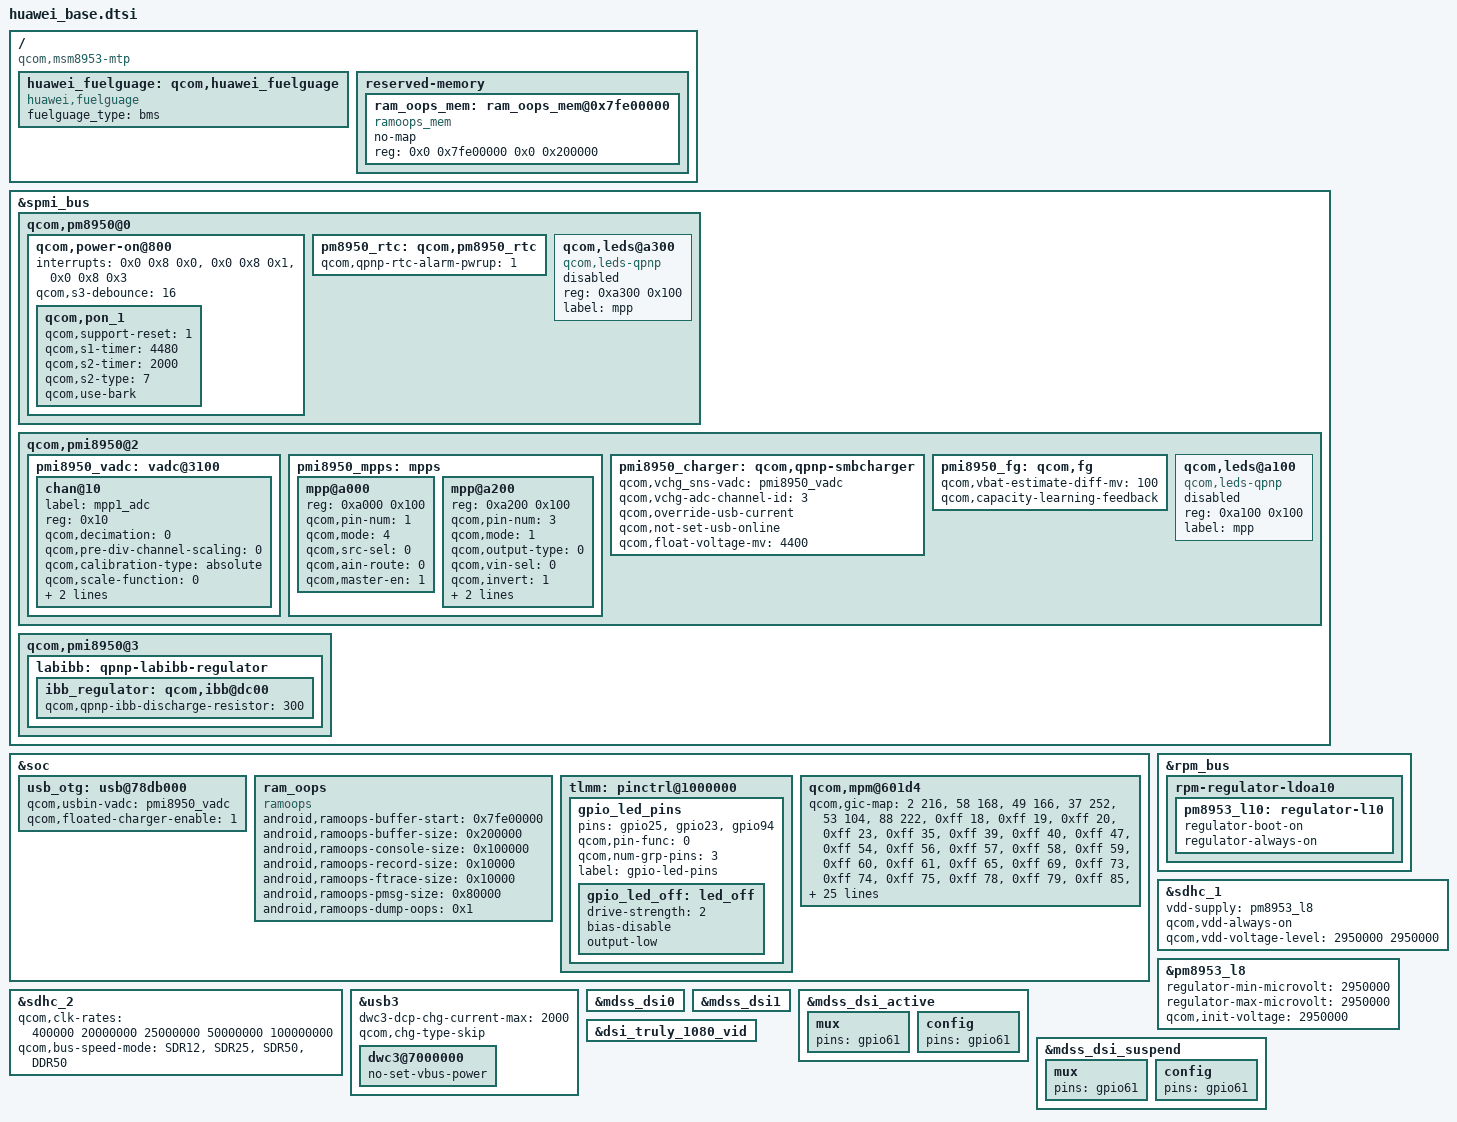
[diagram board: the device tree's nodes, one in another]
/*=============================================================================

                              Huawei Base Dtsi File

GENERAL DESCRIPTION
  This file is for include the Communal node

Copyright 2010-2014 by HUAWEI Technologies, Inc.  All Rights Reserved.
=============================================================================*/
#include "huawei_antenna_board_detect.dtsi"
#include "msm8953.dtsi"
#include "msm8953-mtp.dtsi"

/ {
	compatible = "qcom,msm8953-mtp", "qcom,msm8953", "qcom,mtp";
};

&spmi_bus {

	qcom,pm8950@0 {
		qcom,power-on@800 {
			interrupts = <0x0 0x8 0x0>,
				<0x0 0x8 0x1>,
				<0x0 0x8 0x3>;
			interrupt-names = "kpdpwr", "resin","kpdpwr-bark";
			qcom,s3-debounce = <16>;

			qcom,pon_1 {
				qcom,support-reset = <1>;
				qcom,s1-timer = <4480>;
				qcom,s2-timer = <2000>;
				qcom,s2-type = <7>;
				qcom,use-bark;
			};
		};

		pm8950_rtc: qcom,pm8950_rtc {
			qcom,qpnp-rtc-alarm-pwrup = <1>;
		};

		qcom,leds@a300 {
			compatible = "qcom,leds-qpnp";
			reg = <0xa300 0x100>;
			label = "mpp";
			status = "disabled";
		};
	};

	qcom,pmi8950@2 {
		pmi8950_vadc: vadc@3100 {
			chan@10 {
				label = "mpp1_adc";
				reg = <0x10>; // channel for MPP1
				qcom,decimation = <0>;
				qcom,pre-div-channel-scaling = <0>; //Use 1:1 scaling to keep input voltage with in Max voltage: 1.8V
				qcom,calibration-type = "absolute";
				qcom,scale-function = <0>;
				qcom,hw-settle-time = <1>;
				qcom,fast-avg-setup = <2>;
			};
		};

		pmi8950_mpps: mpps {
			mpp@a000 {
				reg = <0xa000 0x100>;
				qcom,pin-num = <1>;
				status = "ok";
				qcom,mode = <4>; // A-input
				qcom,src-sel = <0>; //MPP Constant
				qcom,ain-route = <0>; // QPNP_PIN_AIN_AMUX_CH5 = 0 for MPP1
				qcom,master-en = <1>; //Enable MPP
			};
			mpp@a200 {
				reg = <0xa200 0x100>;
				qcom,pin-num = <3>;
				qcom,mode = <1>;
				qcom,output-type = <0>;
				qcom,vin-sel = <0>;
				qcom,invert = <1>;
				qcom,src-sel = <0>;
				qcom,master-en = <1>;
				status = "okay";
			};
		};

		pmi8950_charger: qcom,qpnp-smbcharger {
			qcom,vchg_sns-vadc = <&pmi8950_vadc>;
			qcom,vchg-adc-channel-id = <3>;
			qcom,override-usb-current;
			qcom,not-set-usb-online;
			qcom,float-voltage-mv = <4400>;
		};

		pmi8950_fg: qcom,fg {
			qcom,vbat-estimate-diff-mv = <100>;
                        qcom,capacity-learning-feedback;
		};

		qcom,leds@a100 {
			compatible = "qcom,leds-qpnp";
			reg = <0xa100 0x100>;
			label = "mpp";
			status = "disabled";
		};
	};
	qcom,pmi8950@3 {
		labibb: qpnp-labibb-regulator {
			ibb_regulator: qcom,ibb@dc00 {
				qcom,qpnp-ibb-discharge-resistor = <300>;
			};
		};
	};
};

/{
	huawei_fuelguage: qcom,huawei_fuelguage{
		compatible = "huawei,fuelguage";
		fuelguage_type = "bms";
		status = "okay";
	};
};

&soc {
	usb_otg: usb@78db000 {
		qcom,usbin-vadc = <&pmi8950_vadc>;
		qcom,floated-charger-enable = <1>;
	};
};

/{
	reserved-memory {
		ram_oops_mem: ram_oops_mem@0x7fe00000 {
		   compatible = "ramoops_mem";
		   no-map;
		   reg = <0x0 0x7fe00000 0x0 0x200000>;
		 };
	};
};

&soc {
	 ram_oops {
		  compatible = "ramoops";
		  android,ramoops-buffer-start 	= <0x7fe00000>;
		  android,ramoops-buffer-size 	= <0x200000>;
		  android,ramoops-console-size 	= <0x100000>;
		  android,ramoops-record-size 	= <0x10000>;
		  android,ramoops-ftrace-size 	= <0x10000>;
		  android,ramoops-pmsg-size 	= <0x80000>;
		  android,ramoops-dump-oops 	= <0x1>;
	 };
};

&soc {
	tlmm: pinctrl@1000000 {
		gpio_led_pins {
			pins ="gpio25", "gpio23", "gpio94";
			qcom,pin-func = <0>;
			qcom,num-grp-pins = <3>;
			label = "gpio-led-pins";
			gpio_led_off: led_off {
				drive-strength = <2>;
				bias-disable;
				output-low;
			};
		};
	};
};

&rpm_bus {
	rpm-regulator-ldoa10 {
		pm8953_l10: regulator-l10 {
			regulator-boot-on;
			regulator-always-on;
		};
	};
};

&sdhc_1 {
	/* device core power supply */
	vdd-supply = <&pm8953_l8>;
	qcom,vdd-always-on;
	qcom,vdd-voltage-level = <2950000 2950000>;
};

&sdhc_2 {
	/* device core power supply */
	qcom,clk-rates = <400000 20000000 25000000 50000000 100000000>;
	qcom,bus-speed-mode = "SDR12", "SDR25", "SDR50", "DDR50";
};


&pm8953_l8 {
	regulator-min-microvolt = <2950000>;
	regulator-max-microvolt = <2950000>;
	qcom,init-voltage = <2950000>;
};

&soc {
	qcom,mpm@601d4 {
		qcom,gic-map = <2 216>, /* tsens_upper_lower_int */
			<58 168>,   /* qusb2phy_dmse_hv -> hs_phy_irq*/
			<49 166>,   /* qusb2phy_dpse_hv -> usb30_pwr_evnt_irq */
			<37 252>,   /* qmp_usb3_lfps_rxterm_irq -> ss_phy_irq */
			<53 104>, /* mdss_irq */
			<88 222>, /* ee0_krait_hlos_spmi_periph_irq */
			<0xff 18>,  /* APC_qgicQTmrSecPhysIrptReq */
			<0xff 19>,  /* APC_qgicQTmrNonSecPhysIrptReq */
			<0xff 20>,  /* qgicQTmrVirtIrptReq */
			<0xff 23>,  /* apss_hm */
			<0xff 35>,  /* WDT_barkInt */
			<0xff 39>,  /* arch_mem_timer */
			<0xff 40>,  /* qtmr_phy_irq[0] */
			<0xff 47>,  /* rbif_irq[0] */
			<0xff 54>,  /* gladiator-error */
			<0xff 56>,  /* q6_wdog_expired_irq */
			<0xff 57>,  /* mss_to_apps_irq(0) */
			<0xff 58>,  /* mss_to_apps_irq(1) */
			<0xff 59>,  /* mss_to_apps_irq(2) */
			<0xff 60>,  /* mss_to_apps_irq(3) */
			<0xff 61>,  /* mss_a2_bam_irq */
			<0xff 65>,  /* o_gc_sys_irq[0] */
			<0xff 69>,  /* vbif_irpt */
			<0xff 73>,  /* app_tcu_gbl_flt_irpt_ns */
			<0xff 74>,  /* smmu_bus_intr[2] */
			<0xff 75>,  /* smmu_bus_intr[3] */
			<0xff 78>,  /* smmu_bus_intr[5] */
			<0xff 79>,  /* smmu_bus_intr[6] */
			<0xff 85>,  /* smmu_bus_intr[31] */
			<0xff 86>,  /* smmu_bus_intr[32] */
			<0xff 90>,  /* smmu_bus_intr[33] */
			<0xff 92>,  /* smmu_bus_intr[34] */
			<0xff 93>,  /* smmu_bus_intr[35] */
			<0xff 97>,  /* smmu_bus_intr[10] */
			<0xff 102>, /* smmu_bus_intr[14] */
			<0xff 108>, /* smmu_bus_intr[36] */
			<0xff 109>, /* smmu_bus_intr[37] */
			<0xff 112>, /* smmu_bus_intr[38] */
			<0xff 114>, /* qdsd_intr_out */
			<0xff 126>, /* app_tcu_cxt_irpt_vec[11] */
			<0xff 128>, /* blsp1_peripheral_irq[3] */
			<0xff 131>, /* qup_irq */
			<0xff 136>, /* app_tcu_cxt_irpt_vec[15] */
			<0xff 137>, /* app_tcu_cxt_irpt_vec[16] */
			<0xff 138>, /* app_tcu_cxt_irpt_vec[17] */
			<0xff 139>, /* uart_dm_intr */
			<0xff 140>, /* uart_dm_intr */
			<0xff 141>, /* app_tcu_cxt_irpt_vec[18] */
			<0xff 142>, /* smmu_bus_intr[47] */
			<0xff 143>, /* smmu_bus_intr[48] */
			<0xff 144>, /* smmu_bus_intr[49] */
			<0xff 145>, /* smmu_bus_intr[50] */
			<0xff 146>, /* smmu_bus_intr[51] */
			<0xff 147>, /* smmu_bus_intr[52] */
			<0xff 148>, /* smmu_bus_intr[53] */
			<0xff 149>, /* smmu_bus_intr[54] */
			<0xff 150>, /* smmu_bus_intr[55] */
			<0xff 151>, /* smmu_bus_intr[56] */
			<0xff 152>, /* smmu_bus_intr[57] */
			<0xff 153>, /* smmu_bus_intr[58] */
			<0xff 155>, /* sdc1_irq(0) */
			<0xff 157>, /* sdc2_irq(0) */
			<0xff 167>, /* usb30_bam_irq[0] */
			<0xff 170>, /* sdc1_pwr_cmd_irq */
			<0xff 172>, /* usb30_ctrl_irq[0] */
			<0xff 173>, /* o_wcss_apss_smd_hi */
			<0xff 174>, /* o_wcss_apss_smd_med */
			<0xff 175>, /* o_wcss_apss_smd_low */
			<0xff 176>, /* o_wcss_apss_smsm_irq */
			<0xff 177>, /* o_wcss_apss_wlan_data_xfer_done */
			<0xff 178>, /* o_wcss_apss_wlan_rx_data_avail */
			<0xff 179>, /* o_wcss_apss_asic_intr */
			<0xff 181>, /* o_wcss_apss_wdog_bite_and_reset_rdy */
			<0xff 188>, /* lpass_irq_out_apcs(0) */
			<0xff 189>, /* lpass_irq_out_apcs(1) */
			<0xff 190>, /* lpass_irq_out_apcs(2) */
			<0xff 191>, /* lpass_irq_out_apcs(3) */
			<0xff 192>, /* lpass_irq_out_apcs(4) */
			<0xff 193>, /* lpass_irq_out_apcs(5) */
			<0xff 194>, /* lpass_irq_out_apcs(6) */
			<0xff 195>, /* lpass_irq_out_apcs(7) */
			<0xff 196>, /* lpass_irq_out_apcs(8) */
			<0xff 197>, /* lpass_irq_out_apcs(9) */
			<0xff 198>, /* coresight-tmc-etr interrupt */
			<0xff 200>, /* rpm_ipc(4) */
			<0xff 201>, /* rpm_ipc(5) */
			<0xff 202>, /* rpm_ipc(6) */
			<0xff 203>, /* rpm_ipc(7) */
			<0xff 204>, /* rpm_ipc(24) */
			<0xff 205>, /* rpm_ipc(25) */
			<0xff 206>, /* rpm_ipc(26) */
			<0xff 207>, /* rpm_ipc(27) */
			<0xff 212>, /* lpass_slimbus_bam_ee1_irq */
			<0xff 215>, /* o_bimc_intr[0] */
			<0xff 224>, /* spdm_realtime_irq[1] */
			<0xff 231>, /* arm-smmu global fault */
			<0xff 239>, /* crypto_bam_irq[1]*/
			<0xff 240>, /* summary_irq_kpss */
			<0xff 253>, /* sdc2_pwr_cmd_irq */
			<0xff 257>, /* osmmu_Cirpt[0] */
			<0xff 260>, /* ipa_irq[0] */
			<0xff 262>, /* ipa_bam_irq[0] */
			<0xff 263>, /* ipa_bam_irq[2] */
			<0xff 264>, /* arm-smmu context fault */
			<0xff 269>, /* rpm_wdog_expired_irq */
			<0xff 270>, /* blsp1_bam_irq[0] */
			<0xff 273>, /* smmu_bus_intr[18] */
			<0xff 274>, /* smmu_bus_intr[19] */
			<0xff 275>, /* rpm_ipc(30) */
			<0xff 276>, /* rpm_ipc(31) */
			<0xff 285>, /* app_tcu_cxt_irpt_vec[0] */
			<0xff 286>, /* app_tcu_cxt_irpt_vec[1] */
			<0xff 287>, /* app_tcu_cxt_irpt_vec[2] */
			<0xff 305>, /* L2_EXTERRIRQ_C0 */
			<0xff 306>, /* L2_EXTERRIRQ_C1 */
			<0xff 307>, /* L2_INTERRIRQ_C0 */
			<0xff 308>, /* L2_INTERRIRQ_C1 */
			<0xff 314>, /* CCISAW_svicInt */
			<0xff 321>, /* q6ss_irq_out(4) */
			<0xff 322>, /* q6ss_irq_out(5) */
			<0xff 323>, /* q6ss_irq_out(6) */
			<0xff 325>, /* q6ss_wdog_exp_irq */
			<0xff 344>, /* sdcc_ice_nonsec_level_irq */
			<0xff 346>, /* tsens_critical_int */
			<0xff 54>,
			<0xff 129>,
			<0xff 271>,
			<0xff 331>,
			<0xff 334>;
	};
};

&usb3 {
	dwc3-dcp-chg-current-max = <2000>;
	qcom,chg-type-skip;
	dwc3@7000000 {
		no-set-vbus-power;
	};
};
&mdss_dsi0 {
	/delete-property/ qcom,platform-bklight-en-gpio;
	/delete-property/ vdd-supply;
};
&mdss_dsi1 {
	/delete-property/ vdd-supply;
};
&mdss_dsi_active {
	mux {
		pins = "gpio61";
	};
	config {
		pins = "gpio61";
	};
};

&mdss_dsi_suspend {
	mux {
		pins = "gpio61";
	};

	config {
		pins = "gpio61";
	};
};
&dsi_truly_1080_vid {
	/delete-property/ qcom,mdss-dsi-pan-enable-dynamic-fps;
	/delete-property/ qcom,mdss-dsi-pan-fps-update;
};
